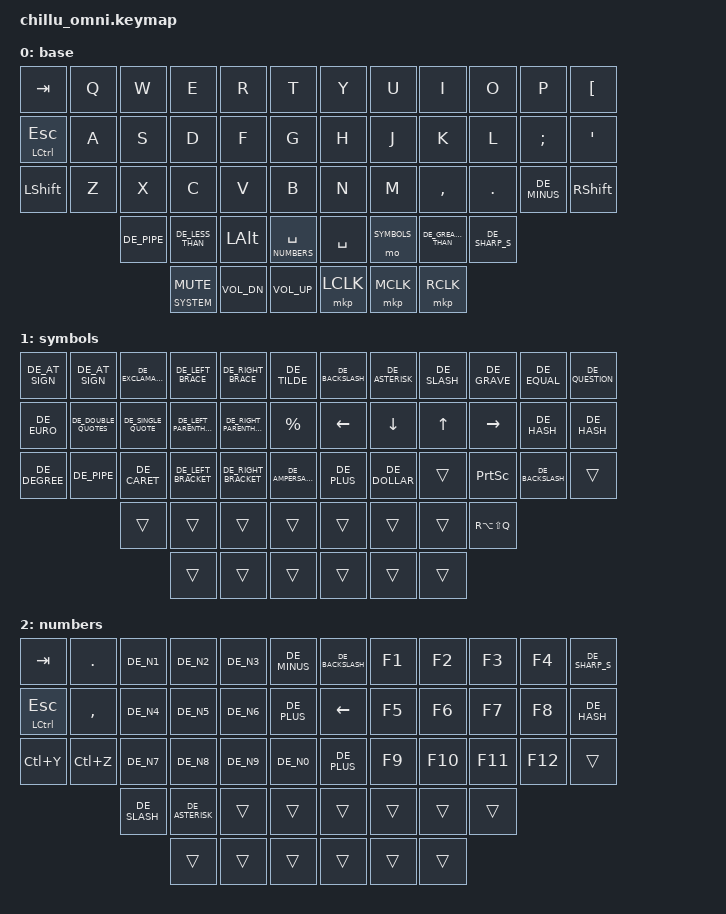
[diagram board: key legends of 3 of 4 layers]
/*
 * Copyright (c) 2020 The ZMK Contributors
 *
 * SPDX-License-Identifier: MIT
 */

#include <behaviors.dtsi>
#include <dt-bindings/zmk/keys.h>
#include <dt-bindings/zmk/bt.h>
#include <locale/keys_de.h>

#define BASE 0
#define SYMBOLS 1
#define NUMBERS 2
#define SYSTEM 3
#define MOUSE_KEYS 4
#define MOUSE_TP 5
#define MOUSE_TP_SET 6

/*
 * Defines to enable/disable features
 *
 * These defines allow us to conditionally enable and disable parts of the keymap config.
 *
 * For example, if we decide to build the firmware without the mouse features, we can
 * disable all the config options that rely on those forks and modules without having
 * to edit the entire keymap file manually every time.
 */

#define HAS_MOUSE_KEYS
#define HAS_MOUSE_TP

#ifdef HAS_MOUSE_KEYS
  #include <dt-bindings/zmk/mouse.h>
  #include <behaviors/mouse_keys.dtsi>
#endif  // HAS_MOUSE_KEYS

#ifdef HAS_MOUSE_TP
  // We store the trackpoint settings in a separate file
  // to make organization a little easier.
  #include "include/mouse_tp.dtsi"
#endif  // HAS_MOUSE_TP



// Adjust layer keys based on enabled features.
//
// This prevents build errors when we build the firmware
// without the mouse keys PR or the TP module.
#ifdef HAS_MOUSE_KEYS
  #define U_THUMB_INNER &mo MOUSE_KEYS
#else
  #define U_THUMB_INNER &none
#endif  // HAS_MOUSE_KEYS

#ifdef HAS_MOUSE_TP
  #define U_TOG_TP_SET &tog MOUSE_TP_SET
#else
  #define U_TOG_TP_SET &none
#endif  // HAS_MOUSE_TP

// Disable line-wrap in your editor to see a "visualization" of the key layouts
/ {
  combos {
    compatible = "zmk,combos";
      combo_backspace_right {
        timeout-ms = <50>;
        key-positions = <8 9>;
        bindings = <&kp BACKSPACE>;
      };
      combo_enter_right {
        timeout-ms = <50>;
        key-positions = <20 21>;
        bindings = <&kp ENTER>;
      };
      combo_del_right {
        timeout-ms = <50>;
        key-positions = <32 33>;
        bindings = <&kp DEL>;
      };
      combo_backspace_left {
        timeout-ms = <50>;
        key-positions = <2 3>;
        bindings = <&kp BACKSPACE>;
      };
      combo_enter_left {
        timeout-ms = <50>;
        key-positions = <14 15>;
        bindings = <&kp ENTER>;
      };
      combo_del_left {
        timeout-ms = <50>;
        key-positions = <26 27>;
        bindings = <&kp DEL>;
      };
  };

  behaviors {
    mo_kp: behavior_mo_kp {
      compatible = "zmk,behavior-hold-tap";
      #binding-cells = <2>;
      flavor = "hold-preferred";
      tapping-term-ms = <200>;
      bindings = <&mo>, <&kp>;
    };

  };

  keymap {
    compatible = "zmk,keymap";

    base_layer {
      display-name = "base";
      bindings = <
// ╭────────────────────────┬────────────────────────┬────────────────────────┬────────────────────────┬────────────────────────┬────────────────────────╮    ╭────────────────────────┬────────────────────────┬────────────────────────┬───────────────────────┬────────────────────────┬────────────────────────╮
     &kp TAB                  &kp Q                    &kp W                    &kp E                    &kp R                    &kp T                         &kp Y                    &kp U                    &kp I                    &kp O                    &kp P                    &kp LEFT_BRACKET
// ├────────────────────────┼────────────────────────┼────────────────────────┼────────────────────────┼────────────────────────┼────────────────────────┤    ├────────────────────────┼────────────────────────┼────────────────────────┼───────────────────────┼────────────────────────┼────────────────────────┤
     &mt LCTRL ESC            &kp A                    &kp S                    &kp D                    &kp F                    &kp G                         &kp H                    &kp J                    &kp K                    &kp L                    &kp SEMICOLON            &kp SINGLE_QUOTE
// ├────────────────────────┼────────────────────────┼────────────────────────┼────────────────────────┼────────────────────────┼────────────────────────┤    ├────────────────────────┼────────────────────────┼────────────────────────┼───────────────────────┼────────────────────────┼────────────────────────┤
     &kp LSHFT                &kp Z                    &kp X                    &kp C                    &kp V                    &kp B                         &kp N                    &kp M                    &kp COMMA                &kp DOT                  &kp DE_MINUS             &kp RSHIFT
// ╰────────────────────────┴────────────────────────┴────────────────────────┴────────────────────────┼────────────────────────┼────────────────────────┤    ├────────────────────────┼────────────────────────┼────────────────────────┼───────────────────────┼────────────────────────┼────────────────────────╯
											    	   &kp DE_PIPE              &kp DE_LESS_THAN         &kp LALT                 &mo_kp NUMBERS SPACE          &kp SPACE                &mo SYMBOLS              &kp DE_GREATER_THAN      &kp DE_SHARP_S
//                                                                            ╰────────────────────────┴────────────────────────┴────────────────────────╯    ╰────────────────────────┴────────────────────────┴────────────────────────╯
                                                                                &mo_kp SYSTEM K_MUTE     &kp K_VOL_DN             &kp K_VOL_UP                  &mkp LCLK                &mkp MCLK                &mkp RCLK
//                                                                            ╰────────────────────────┴────────────────────────┴────────────────────────╯    ╰────────────────────────┴────────────────────────┴────────────────────────╯

      >;
    };


    symbol_layer {
      display-name = "symbols";
      bindings = <
// ╭────────────────────────┬────────────────────────┬────────────────────────┬────────────────────────┬────────────────────────┬────────────────────────╮    ╭────────────────────────┬────────────────────────┬────────────────────────┬────────────────────────┬────────────────────────┬────────────────────────╮
     &kp DE_AT_SIGN           &kp DE_AT_SIGN           &kp DE_EXCLAMATION       &kp DE_LEFT_BRACE        &kp DE_RIGHT_BRACE       &kp DE_TILDE                  &kp DE_BACKSLASH         &kp DE_ASTERISK          &kp DE_SLASH             &kp DE_GRAVE             &kp DE_EQUAL              &kp DE_QUESTION
// ├────────────────────────┼────────────────────────┼────────────────────────┼────────────────────────┼────────────────────────┼────────────────────────┤    ├────────────────────────┼────────────────────────┼────────────────────────┼────────────────────────┼────────────────────────┼────────────────────────┤
     &kp DE_EURO              &kp DE_DOUBLE_QUOTES     &kp DE_SINGLE_QUOTE      &kp DE_LEFT_PARENTHESIS  &kp DE_RIGHT_PARENTHESIS &kp PERCENT                   &kp LEFT                 &kp DOWN                 &kp UP                   &kp RIGHT                &kp DE_HASH               &kp DE_HASH
// ├────────────────────────┼────────────────────────┼────────────────────────┼────────────────────────┼────────────────────────┼────────────────────────┤    ├────────────────────────┼────────────────────────┼────────────────────────┼────────────────────────┼────────────────────────┼────────────────────────┤
     &kp DE_DEGREE            &kp DE_PIPE              &kp DE_CARET             &kp DE_LEFT_BRACKET      &kp DE_RIGHT_BRACKET     &kp DE_AMPERSAND              &kp DE_PLUS              &kp DE_DOLLAR            &trans                   &kp PRINTSCREEN          &kp DE_BACKSLASH          &trans
// ╰────────────────────────┴────────────────────────┴────────────────────────┴────────────────────────┼────────────────────────┼────────────────────────┤    ├────────────────────────┼────────────────────────┼────────────────────────┼────────────────────────┴────────────────────────┼────────────────────────╯
                                                       &trans                   &trans                   &trans                   &trans                        &trans                   &trans                   &trans                   &kp RA(LS(Q))
//                                                                            ╰────────────────────────┴────────────────────────┴────────────────────────╯    ╰────────────────────────┴────────────────────────┴────────────────────────╯
                                                                                &trans                   &trans                   &trans                        &trans                   &trans                   &trans
//                                                                            ╰────────────────────────┴────────────────────────┴────────────────────────╯    ╰────────────────────────┴────────────────────────┴────────────────────────╯
      >;
    };


    number_layer {
      display-name = "numbers";
      bindings = <
// ╭────────────────────────┬────────────────────────┬────────────────────────┬────────────────────────┬────────────────────────┬────────────────────────╮    ╭────────────────────────┬────────────────────────┬────────────────────────┬────────────────────────┬────────────────────────┬────────────────────────╮
     &kp TAB                  &kp DOT                  &kp DE_N1                &kp DE_N2                &kp DE_N3                &kp DE_MINUS                  &kp DE_BACKSLASH         &kp F1                   &kp F2                   &kp F3                   &kp F4                   &kp DE_SHARP_S
// ├────────────────────────┼────────────────────────┼────────────────────────┼────────────────────────┼────────────────────────┼────────────────────────┤    ├────────────────────────┼────────────────────────┼────────────────────────┼────────────────────────┼────────────────────────┼────────────────────────┤
     &mt LCTRL ESC            &kp COMMA                &kp DE_N4                &kp DE_N5                &kp DE_N6                &kp DE_PLUS                   &kp LEFT                 &kp F5                   &kp F6                   &kp F7                   &kp F8                   &kp DE_HASH
// ├────────────────────────┼────────────────────────┼────────────────────────┼────────────────────────┼────────────────────────┼────────────────────────┤    ├────────────────────────┼────────────────────────┼────────────────────────┼────────────────────────┼────────────────────────┼────────────────────────┤
     &kp LC(Y)                &kp LC(Z)                &kp DE_N7                &kp DE_N8                &kp DE_N9                &kp DE_N0                     &kp DE_PLUS              &kp F9                   &kp F10                  &kp F11                  &kp F12                  &trans
// ╰────────────────────────┴────────────────────────┴────────────────────────┴────────────────────────┼────────────────────────┼────────────────────────┤    ├────────────────────────┼────────────────────────┼────────────────────────┼────────────────────────┴────────────────────────┼────────────────────────╯
                                                       &kp DE_SLASH             &kp DE_ASTERISK          &trans                   &trans                        &trans                   &trans                   &trans                   &trans
//                                                                            ╰────────────────────────┴────────────────────────┴────────────────────────╯    ╰────────────────────────┴────────────────────────┴────────────────────────╯
                                                                                &trans                   &trans                   &trans                        &trans                   &trans                   &trans
//                                                                            ╰────────────────────────┴────────────────────────┴────────────────────────╯    ╰────────────────────────┴────────────────────────┴────────────────────────╯
      >;
    };

    system_layer {
      display-name = "system";
      bindings = <
// ╭────────────────────────┬────────────────────────┬────────────────────────┬────────────────────────┬────────────────────────┬────────────────────────╮    ╭────────────────────────┬────────────────────────┬────────────────────────┬────────────────────────┬────────────────────────┬────────────────────────╮
     U_TOG_TP_SET             U_TOG_TP_SET             &none                    U_MSS_TP_S_D             U_MSS_TP_S_I             U_MSS_TP_PT_I                 &bt BT_SEL 0             &bt BT_SEL 1             &bt BT_SEL 2             &none                    U_TOG_TP_SET              U_TOG_TP_SET
// ├────────────────────────┼────────────────────────┼────────────────────────┼────────────────────────┼────────────────────────┼────────────────────────┤    ├────────────────────────┼────────────────────────┼────────────────────────┼────────────────────────┼────────────────────────┼────────────────────────┤
     U_MSS_RESET              U_MSS_RESET              &none                    U_MSS_TP_NI_D            U_MSS_TP_NI_I            U_MSS_TP_PT_D                 &bt BT_DISC 0            &bt BT_DISC 1            &bt BT_DISC 2            &none                    U_MSS_RESET               U_MSS_RESET
// ├────────────────────────┼────────────────────────┼────────────────────────┼────────────────────────┼────────────────────────┼────────────────────────┤    ├────────────────────────┼────────────────────────┼────────────────────────┼────────────────────────┼────────────────────────┼────────────────────────┤
     U_MSS_LOG                U_MSS_LOG                &sys_reset               U_MSS_TP_V6_D            U_MSS_TP_V6_I            &kp A                         &bt BT_CLR               U_MSS_TP_V6_D            U_MSS_TP_V6_I            &sys_reset               U_MSS_LOG                 U_MSS_LOG
// ╰────────────────────────┴────────────────────────┴────────────────────────┴────────────────────────┼────────────────────────┼────────────────────────┤    ├────────────────────────┼────────────────────────┼────────────────────────┼────────────────────────┴────────────────────────┼────────────────────────╯
                                                       &trans                   &trans                   &mkp LCLK                &mkp RCLK                     &none                    &trans                   &mkp RCLK                &mkp RCLK
//                                                                            ╰────────────────────────┴────────────────────────┴────────────────────────╯    ╰────────────────────────┴────────────────────────┴────────────────────────╯
                                                                                &trans                   &mkp LCLK                &mkp RCLK                     &mkp LCLK                &mkp MCLK                &mkp RCLK
//                                                                            ╰────────────────────────┴────────────────────────┴────────────────────────╯    ╰────────────────────────┴────────────────────────┴────────────────────────╯
      >;
    };

  };
};
